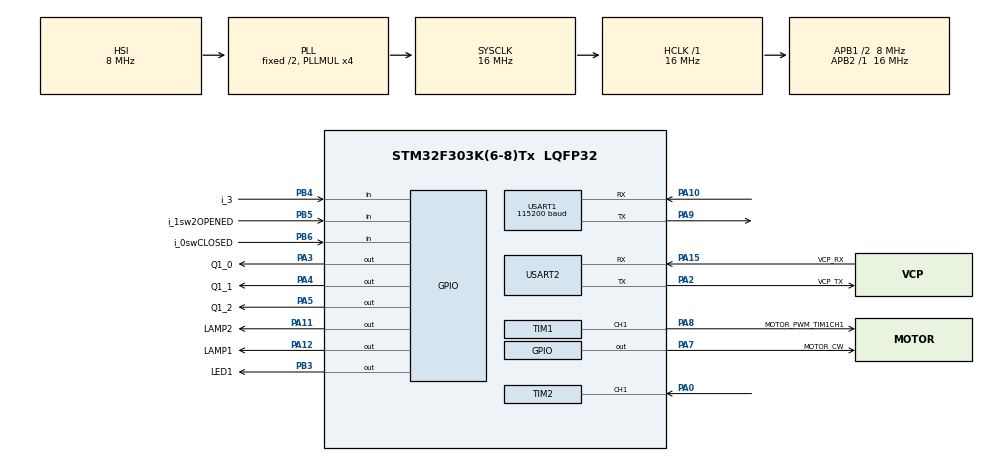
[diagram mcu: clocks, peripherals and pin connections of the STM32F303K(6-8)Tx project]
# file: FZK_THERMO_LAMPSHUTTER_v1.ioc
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Dma.Request0=USART1_TX
Dma.Request1=USART1_RX
Dma.USART1_RX.1.Direction=DMA_PERIPH_TO_MEMORY
Dma.USART1_RX.1.Instance=DMA1_Channel5
Dma.USART1_RX.1.MemDataAlignment=DMA_MDATAALIGN_BYTE
Dma.USART1_RX.1.MemInc=DMA_MINC_ENABLE
Dma.USART1_RX.1.Mode=DMA_NORMAL
Dma.USART1_RX.1.PeriphDataAlignment=DMA_PDATAALIGN_BYTE
Dma.USART1_RX.1.PeriphInc=DMA_PINC_DISABLE
Dma.USART1_RX.1.Priority=DMA_PRIORITY_LOW
Dma.USART1_TX.0.Direction=DMA_MEMORY_TO_PERIPH
Dma.USART1_TX.0.Instance=DMA1_Channel4
Dma.USART1_TX.0.MemDataAlignment=DMA_MDATAALIGN_BYTE
Dma.USART1_TX.0.MemInc=DMA_MINC_ENABLE
Dma.USART1_TX.0.Mode=DMA_NORMAL
Dma.USART1_TX.0.PeriphDataAlignment=DMA_PDATAALIGN_BYTE
Dma.USART1_TX.0.PeriphInc=DMA_PINC_DISABLE
Dma.USART1_TX.0.Priority=DMA_PRIORITY_LOW
FREERTOS.Tasks01=defaultTask,0,128,StartDefaultTask,Default,NULL,Dynamic,NULL,NULL
FREERTOS.configUSE_NEWLIB_REENTRANT=1
Mcu.Family=STM32F3
Mcu.Name=STM32F303K(6-8)Tx
Mcu.Package=LQFP32
NVIC.DMA1_Channel4_IRQn=true\:5\:0\:false\:false\:true\:true\:false\:true\:true
NVIC.DMA1_Channel5_IRQn=true\:5\:0\:false\:false\:true\:true\:false\:true\:true
NVIC.PriorityGroup=NVIC_PRIORITYGROUP_4
NVIC.TIM1_UP_TIM16_IRQn=true\:15\:0\:false\:false\:true\:false\:false\:true\:true
NVIC.TimeBase=TIM1_UP_TIM16_IRQn
NVIC.TimeBaseIP=TIM16
NVIC.USART1_IRQn=true\:5\:0\:false\:false\:true\:true\:true\:true\:true
PA0.Signal=S_TIM2_CH1_ETR
PA10.Mode=Asynchronous
PA10.Signal=USART1_RX
PA11.GPIO_Label=LAMP2
PA11.Signal=GPIO_Output
PA12.GPIO_Label=LAMP1
PA12.Signal=GPIO_Output
PA13.GPIO_Label=SWDIO
PA13.Mode=Serial_Wire
PA13.Signal=SYS_JTMS-SWDIO
PA14.GPIO_Label=SWCLK
PA14.Mode=Serial_Wire
PA14.Signal=SYS_JTCK-SWCLK
PA15.GPIO_Label=VCP_RX
PA15.Mode=Asynchronous
PA15.Signal=USART2_RX
PA2.GPIO_Label=VCP_TX
PA2.Mode=Asynchronous
PA2.Signal=USART2_TX
PA3.GPIO_Label=Q1_0
PA3.Signal=GPIO_Output
PA4.GPIO_Label=Q1_1
PA4.Signal=GPIO_Output
PA5.GPIO_Label=Q1_2
PA5.Signal=GPIO_Output
PA7.GPIO_Label=MOTOR_CW
PA7.Signal=GPIO_Output
PA8.GPIO_Label=MOTOR_PWM_TIM1CH1
PA8.Signal=S_TIM1_CH1
PA9.Mode=Asynchronous
PA9.Signal=USART1_TX
PB3.GPIO_Label=LED1
PB3.Signal=GPIO_Output
PB4.GPIO_Label=i_3
PB4.Signal=GPIO_Input
PB5.GPIO_Label=i_1sw2OPENED
PB5.Signal=GPIO_Input
PB6.GPIO_Label=i_0swCLOSED
PB6.Signal=GPIO_Input
PF0\ /\ OSC_IN.GPIO_Label=MCO
PF0\ /\ OSC_IN.Mode=HSE-External-Clock-Source
PF0\ /\ OSC_IN.Signal=RCC_OSC_IN
ProjectManager.HeapSize=0x200
ProjectManager.StackSize=0x400
ProjectManager.TargetToolchain=STM32CubeIDE
RCC.AHBFreq_Value=16000000
RCC.APB1CLKDivider=RCC_HCLK_DIV2
RCC.APB1Freq_Value=8000000
RCC.APB1TimFreq_Value=16000000
RCC.APB2Freq_Value=16000000
RCC.APB2TimFreq_Value=16000000
RCC.CortexFreq_Value=16000000
RCC.HCLKFreq_Value=16000000
RCC.HSE_VALUE=8000000
RCC.HSI_VALUE=8000000
RCC.PLLMUL=RCC_PLL_MUL4
RCC.SYSCLKFreq_VALUE=16000000
RCC.SYSCLKSourceVirtual=RCC_SYSCLKSOURCE_PLLCLK
SH.S_TIM1_CH1.0=TIM1_CH1,PWM Generation1 CH1
SH.S_TIM2_CH1_ETR.0=TIM2_CH1,Input_Capture1_from_TI1
TIM1.Channel-Input_Capture4_from_TI4=TIM_CHANNEL_4
TIM1.Channel-PWM\ Generation1\ CH1=TIM_CHANNEL_1
TIM1.OCMode_PWM-PWM\ Generation1\ CH1=TIM_OCMODE_PWM2
TIM1.Period=100-1
TIM1.Prescaler=10-1
TIM1.Pulse-PWM\ Generation1\ CH1=50-1
TIM2.Channel-Input_Capture1_from_TI1=TIM_CHANNEL_1
USART1.BaudRate=115200
USART1.VirtualMode-Asynchronous=VM_ASYNC
USART2.VirtualMode-Asynchronous=VM_ASYNC
VP_FREERTOS_VS_CMSIS_V1.Mode=CMSIS_V1
VP_SYS_VS_tim16.Mode=TIM16
VP_TIM1_VS_ClockSourceINT.Mode=Internal
board=NUCLEO-F303K8

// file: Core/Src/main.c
/* USER CODE BEGIN Header */
/**
 ******************************************************************************
 * @file           : main.c
 * @brief          : Main program body
 ******************************************************************************
 * @attention
 *
 * Copyright (c) 2025 STMicroelectronics.
 * All rights reserved.
 *
 * This software is licensed under terms that can be found in the LICENSE file
 * in the root directory of this software component.
 * If no LICENSE file comes with this software, it is provided AS-IS.
 *
 ******************************************************************************
 ******************************************************************************
 Прошивка управления лампами нагрева и заслонкой термографа.
 Связь: USART1 115200 8N1 через модуль USR-TCP232-T2. Протокол описан в protocol.c.
 Задачи: заслонка (defaultTask), разбор команд, лампы, передача UART.
 Концевики: PB5 - открыто, PB6 - закрыто (активный уровень низкий).
 */
/* USER CODE END Header */
#include "main.h"
#include "cmsis_os.h"
#include "dma.h"
#include "tim.h"
#include "usart.h"
#include "gpio.h"

/* USER CODE BEGIN Includes */
#include "app.h"
/* USER CODE END Includes */

void SystemClock_Config(void);
void MX_FREERTOS_Init(void);

int main(void)
{

  /* MCU Configuration--------------------------------------------------------*/

  /* Reset of all peripherals, Initializes the Flash interface and the Systick. */
  HAL_Init();

  /* USER CODE BEGIN Init */
  app_early_init();   /* PA8 в «стоп», лампы и CW выключены до любой другой инициализации */
  /* USER CODE END Init */

  /* Configure the system clock */
  SystemClock_Config();

  /* Initialize all configured peripherals */
  MX_GPIO_Init();
  MX_DMA_Init();
  MX_USART2_UART_Init();
  MX_USART1_UART_Init();
  MX_TIM1_Init();
  MX_TIM2_Init();
  /* USER CODE BEGIN 2 */
  app_init();
  /* USER CODE END 2 */

  /* Call init function for freertos objects (in cmsis_os2.c) */
  MX_FREERTOS_Init();

  /* Start scheduler */
  osKernelStart();

  /* We should never get here as control is now taken by the scheduler */

  /* Infinite loop */
  while (1)
  {

  }
}

void SystemClock_Config(void)
{
  RCC_OscInitTypeDef RCC_OscInitStruct = {0};
  RCC_ClkInitTypeDef RCC_ClkInitStruct = {0};
  RCC_PeriphCLKInitTypeDef PeriphClkInit = {0};

  /** Initializes the RCC Oscillators according to the specified parameters
  * in the RCC_OscInitTypeDef structure.
  */
  RCC_OscInitStruct.OscillatorType = RCC_OSCILLATORTYPE_HSI;
  RCC_OscInitStruct.HSIState = RCC_HSI_ON;
  RCC_OscInitStruct.HSICalibrationValue = RCC_HSICALIBRATION_DEFAULT;
  RCC_OscInitStruct.PLL.PLLState = RCC_PLL_ON;
  RCC_OscInitStruct.PLL.PLLSource = RCC_PLLSOURCE_HSI;
  RCC_OscInitStruct.PLL.PLLMUL = RCC_PLL_MUL4;
  if (HAL_RCC_OscConfig(&RCC_OscInitStruct) != HAL_OK)
  {
    Error_Handler();
  }

  /** Initializes the CPU, AHB and APB buses clocks
  */
  RCC_ClkInitStruct.ClockType = RCC_CLOCKTYPE_HCLK|RCC_CLOCKTYPE_SYSCLK
                              |RCC_CLOCKTYPE_PCLK1|RCC_CLOCKTYPE_PCLK2;
  RCC_ClkInitStruct.SYSCLKSource = RCC_SYSCLKSOURCE_PLLCLK;
  RCC_ClkInitStruct.AHBCLKDivider = RCC_SYSCLK_DIV1;
  RCC_ClkInitStruct.APB1CLKDivider = RCC_HCLK_DIV2;
  RCC_ClkInitStruct.APB2CLKDivider = RCC_HCLK_DIV1;

  if (HAL_RCC_ClockConfig(&RCC_ClkInitStruct, FLASH_LATENCY_0) != HAL_OK)
  {
    Error_Handler();
  }
  PeriphClkInit.PeriphClockSelection = RCC_PERIPHCLK_USART1|RCC_PERIPHCLK_TIM1;
  PeriphClkInit.Usart1ClockSelection = RCC_USART1CLKSOURCE_PCLK1;
  PeriphClkInit.Tim1ClockSelection = RCC_TIM1CLK_HCLK;
  if (HAL_RCCEx_PeriphCLKConfig(&PeriphClkInit) != HAL_OK)
  {
    Error_Handler();
  }
}

void HAL_TIM_PeriodElapsedCallback(TIM_HandleTypeDef *htim)
{
  if (htim->Instance == TIM16)
  {
    HAL_IncTick();
  }
}

void Error_Handler(void)
{
  /* USER CODE BEGIN Error_Handler_Debug */
  app_fatal();       /* безопасные выходы и перезагрузка */
  /* USER CODE END Error_Handler_Debug */
}

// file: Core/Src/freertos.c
/* USER CODE BEGIN Header */
/**
 ******************************************************************************
 * File Name          : freertos.c
 * Description        : Code for freertos applications
 ******************************************************************************
 * @attention
 *
 * Copyright (c) 2025 STMicroelectronics.
 * All rights reserved.
 *
 * This software is licensed under terms that can be found in the LICENSE file
 * in the root directory of this software component.
 * If no LICENSE file comes with this software, it is provided AS-IS.
 *
 ******************************************************************************
 */
/* USER CODE END Header */

#include "FreeRTOS.h"
#include "task.h"
#include "main.h"
#include "cmsis_os.h"

/* USER CODE BEGIN Includes */
#include "app.h"
#include "shutter.h"
/* USER CODE END Includes */

osThreadId defaultTaskHandle;

void StartDefaultTask(void const *argument);

void MX_FREERTOS_Init(void); /* (MISRA C 2004 rule 8.1) */

/* GetIdleTaskMemory prototype (linked to static allocation support) */
void vApplicationGetIdleTaskMemory(StaticTask_t **ppxIdleTaskTCBBuffer,
		StackType_t **ppxIdleTaskStackBuffer, uint32_t *pulIdleTaskStackSize);

/* USER CODE BEGIN GET_IDLE_TASK_MEMORY */
static StaticTask_t xIdleTaskTCBBuffer;
static StackType_t xIdleStack[configMINIMAL_STACK_SIZE];

void vApplicationGetIdleTaskMemory(StaticTask_t **ppxIdleTaskTCBBuffer,
		StackType_t **ppxIdleTaskStackBuffer, uint32_t *pulIdleTaskStackSize) {
	*ppxIdleTaskTCBBuffer = &xIdleTaskTCBBuffer;
	*ppxIdleTaskStackBuffer = &xIdleStack[0];
	*pulIdleTaskStackSize = configMINIMAL_STACK_SIZE;
	/* place for user code */
}
/* USER CODE END GET_IDLE_TASK_MEMORY */

void MX_FREERTOS_Init(void) {

	/* Create the thread(s) */
	/* definition and creation of defaultTask */
	osThreadDef(defaultTask, StartDefaultTask, osPriorityNormal, 0, 128);
	defaultTaskHandle = osThreadCreate(osThread(defaultTask), NULL);

	/* USER CODE BEGIN RTOS_THREADS */
	app_create_tasks();
	/* USER CODE END RTOS_THREADS */

}

void StartDefaultTask(void const *argument) {
	/* USER CODE BEGIN StartDefaultTask */
	/* defaultTask = задача заслонки (мотор, концевики, сторожевой таймер) */
	shutter_task_run();
  /* USER CODE END StartDefaultTask */
}
